# STM32U083 register map
File version: 0.2
CPU: CM0+ r0p1, little endian, MPU, no FPU, 4 interrupt priority bits
Registers are 32-bit, read-write, reset 0x0 unless marked. A register's access mark holds for its fields unless they carry their own. Offsets are from the block's base; [hi:lo] are bit positions; {n}, {i} and the like mark numbered series; 'fields as' and 'values as' point back to an identical list; <NAME> marks a mode.

## LCD — LCD address block description
Base 0x40002400
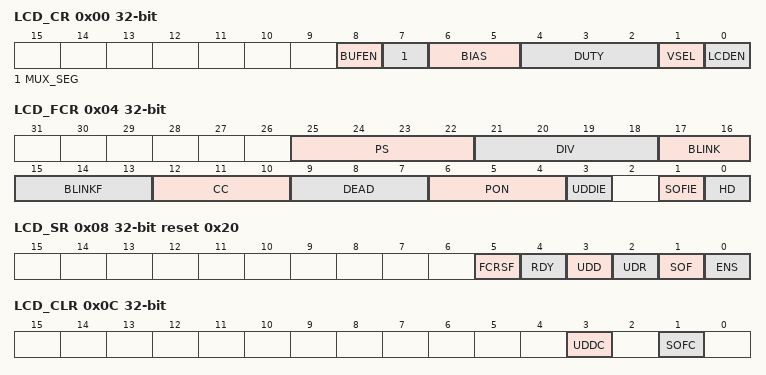
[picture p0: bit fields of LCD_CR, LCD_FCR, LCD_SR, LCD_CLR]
0x00 LCD_CR — LCD control register
  [8] BUFEN — Voltage output buffer enable This bit is used to enable/disable the voltage output buffer for higher driving capability.
    0=Output buffer disabled; 1=Output buffer enabled
  [7] MUX_SEG — Mux segment enable This bit is used to enable SEG pin remapping. Four SEG pins can be multiplexed with1SEG[31:28] or SEG[15:12]. See Section118.3.7.
    0=SEG pin multiplexing disabled; 1=SEG[31:28] multiplexed with SEG[43:40]
  [6:5] BIAS — Bias selector These bits determine the bias used. Value 11 is forbidden.
    0=Bias 1/4; 1=Bias 1/2; 2=Bias 1/3
  [4:2] DUTY — Duty selection These bits determine the duty cycle. Values 101, 110 and 111 are forbidden. Others: Reserved
    0=Static duty; 1=1/2 duty; 2=1/3 duty; 3=1/4 duty; 4=1/8 duty
  [1] VSEL — Voltage source selection This bit determines the voltage source for the LCD.
    0=Internal source (voltage stepup converter); 1=External source (VLCD pin)
  [0] LCDEN — LCD controller enable This bit is set by software to enable the LCD controller/driver. It is cleared by software to turn off the LCD at the beginning of the next frame. When the LCD is disabled, all COM and SEG pins are driven to V<sub>SS</sub>.
    0=LCD controller disabled; 1=LCD controller enabled
0x04 LCD_FCR — LCD frame control register
  [25:22] PS — PS 16-bit prescaler These bits are written by software to define the division factor of the PS 16-bit prescaler. ck_ps = LCDCLK/(2<sup>PS[3:0]</sup>). See<sub> </sub>Section118.3.2. ...
    0=ck_ps = LCDCLK; 1=ck_ps = LCDCLK/2; 15=ck_ps = LCDCLK/32768
  [21:18] DIV — DIV clock divider These bits are written by software to define the division factor of the DIV divider (see1Section118.3.2.) ...
    0=ck_div = ck_ps/16; 1=ck_div = ck_ps/17; 15=ck_div = ck_ps/31
  [17:16] BLINK — Blink mode selection
    0=Blink disabled; 1=Blink enabled on SEG[0], COM[0] (1 pixel); 2=Blink enabled on SEG[0], all COMs (up to 8 pixels depending on the programmed duty); 3=Blink enabled on all SEGs and all COMs (all pixels)
  [15:13] BLINKF — Blink frequency selection
    0=f<sub>LCD</sub>/8; 1=f<sub>LCD</sub>/16; 2=f<sub>LCD</sub>/32; 3=f<sub>LCD</sub>/64; 4=f<sub>LCD</sub>/128; 5=f<sub>LCD</sub>/256; 6=f<sub>LCD</sub>/512; 7=f<sub>LCD</sub>/1024
  [12:10] CC — Contrast control These bits specify one of the V<sub>LCD </sub>maximum voltages (independent of V<sub>DD</sub>). It ranges from12.60 V to 3.51V. Note: Refer to the datasheet for the V<sub>LCDx</sub> values.
    {v}=V<sub>LCD{v}</sub> (v=0..7)
  [9:7] DEAD — Dead time duration These bits are written by software to configure the length of the dead time between frames. During the dead time the COM and SEG voltage levels are held at 0 V to reduce the contrast without modifying the frame rate. ......
    0=No dead time; 1=1 phase period dead time; 2=2 phase period dead time; 7=7 phase period dead time
  [6:4] PON — Pulse ON duration These bits are written by software to define the pulse duration in terms of ck_ps pulses. A1short pulse leads to lower power consumption, but displays with high internal resistance may need a longer pulse to achieve satisfactory contrast. Note that the pulse is never longer than one half prescaled LCD clock period. PON duration example with LCDCLK = 32.7681kHz and PS=0x03:
    0=0 1s; 1=244 1s; 2=488 1s; 3=782 1s; 4=976 1s; 5=1.22 ms; 6=1.46 ms; 7=1.71 ms
  [3] UDDIE — Update display done interrupt enable This bit is set and cleared by software.
    0=LCD update display done interrupt disabled; 1=LCD update display done interrupt enabled
  [1] SOFIE — Start of frame interrupt enable This bit is set and cleared by software.
    0=LCD start-of-frame interrupt disabled; 1=LCD start-of-frame interrupt enabled
  [0] HD — High drive enable This bit is written by software to enable a low resistance divider. Displays with high internal resistance may need a longer drive time to achieve satisfactory contrast. This bit is useful in this case if some additional power consumption can be tolerated.
    0=Permanent high drive disabled; 1=Permanent high drive enabled. When HD = 1, PON[2:0] must be programmed to 001.
0x08 LCD_SR access per field reset 0x20 — LCD status register
  [5] FCRSF ro — LCD frame control register synchronization flag This bit is set by hardware each time the LCD_FCR register is updated in the LCDCLK domain. It is cleared by hardware when writing to the LCD_FCR register.
    0=LCD frame control register not yet synchronized; 1=LCD frame control register synchronized
  [4] RDY ro — Ready flag This bit is set and cleared by hardware. It indicates the status of the stepup converter.
    0=Not ready; 1=Stepup converter enabled and ready to provide the correct voltage
  [3] UDD ro — Update display done This bit is set by hardware. It is cleared by writing 1 to UDDC in LCD_CLR. The bit set has priority over the clear. Note: If the device is in Stop mode (PCLK not provided), UDD does not generate an interrupt even if UDDIE = 1. If the display is not enabled, the UDD interrupt never occurs.
    0=No event; 1=Update display request done. A UDD interrupt is generated if UDDIE = 1 in LCD_FCR.
  [2] UDR rw — Update display request Each time software modifies the LCD_RAM, it must set this bit to transfer the updated data to the second level buffer. This bit stays set until the end of the update. During this time, the LCD_RAM is write protected. When the display is disabled, the update is performed for all LCD_DISPLAY locations. When the display is enabled, the update is performed only for locations for which commons are active (depending on DUTY). For example if DUTY = 1/2, Note: only the LCD_DISPLAY of COM0 and COM1 are updated. Note: Writing 0 on this bit or writing 1 when it is already 1 has no effect. This bit can be cleared by hardware only. It can be cleared only when LCDEN = 1
    0=No effect; 1=Update display request
  [1] SOF ro — Start-of-frame flag This bit is set by hardware at the beginning of a new frame, at the same time as the display data is updated. It is cleared by writing a 1 to SOFC in LCD_CLR. The bit clear has priority over the set.
    0=No event; 1=Start-of-frame event occurred. An LCD SOF interrupt is generated if SOFIE is set.
  [0] ENS ro — LCD enabled status This bit is set and cleared by hardware. It indicates the LCD controller status. Note: This bit is set immediately when LCDEN in LCD_CR goes from 0 to 1. On deactivation, it reflects the real LCD status. It becomes 0 at the end of the last displayed frame.
    0=LCD controller disabled; 1=LCD controller enabled
0x0C LCD_CLR wo — LCD clear register
  [3] UDDC — Update display done clear This bit is written by software to clear UDD in LCD_SR.
    0=No effect; 1=Clear UDD flag
  [1] SOFC — Start-of-frame flag clear This bit is written by software to clear SOF in LCD_SR.
    0=No effect; 1=Clear SOF flag
0x14 LCD_RAM0 — LCD display memory
  [31:0] SEGMENT_DATA — Each bit corresponds to one pixel of the LCD display.
    0=Pixel inactive; 1=Pixel active
0x18 LCD_RAM1 — LCD display memory
  [19:0] SEGMENT_DATA — Each bit corresponds to one pixel of the LCD display.
    0=Pixel inactive; 1=Pixel active
0x1C LCD_RAM2 — LCD display memory
  fields as LCD_RAM0
0x20 LCD_RAM3 — LCD display memory
  fields as LCD_RAM1
0x24 LCD_RAM4 — LCD display memory
  fields as LCD_RAM0
0x28 LCD_RAM5 — LCD display memory
  fields as LCD_RAM1
0x2C LCD_RAM6 — LCD display memory
  fields as LCD_RAM0
0x30 LCD_RAM7 — LCD display memory
  fields as LCD_RAM1
0x34 LCD_RAM8 — LCD display memory
  fields as LCD_RAM0
0x38 LCD_RAM9 — LCD display memory
  [15:0] SEGMENT_DATA — Each bit corresponds to one pixel of the LCD display.
    0=Pixel inactive; 1=Pixel active
0x3C LCD_RAM10 — LCD display memory
  fields as LCD_RAM0
0x40 LCD_RAM11 — LCD display memory
  fields as LCD_RAM9
0x44 LCD_RAM12 — LCD display memory
  fields as LCD_RAM0
0x48 LCD_RAM13 — LCD display memory
  fields as LCD_RAM9
0x4C LCD_RAM14 — LCD display memory
  fields as LCD_RAM0
0x50 LCD_RAM15 — LCD display memory
  fields as LCD_RAM9
